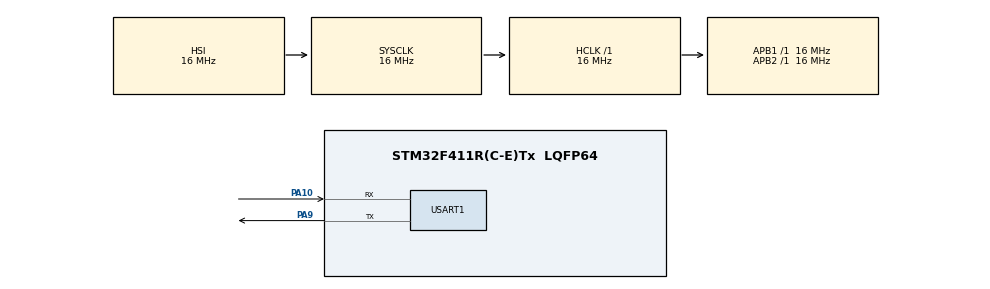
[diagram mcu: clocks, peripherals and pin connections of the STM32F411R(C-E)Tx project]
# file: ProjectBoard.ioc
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Mcu.Family=STM32F4
Mcu.Name=STM32F411R(C-E)Tx
Mcu.Package=LQFP64
NVIC.PriorityGroup=NVIC_PRIORITYGROUP_4
NVIC.USART1_IRQn=true\:0\:0\:false\:false\:true\:true\:true\:true
PA10.Mode=Asynchronous
PA10.Signal=USART1_RX
PA9.Mode=Asynchronous
PA9.Signal=USART1_TX
ProjectManager.HeapSize=0x200
ProjectManager.StackSize=0x400
ProjectManager.TargetToolchain=STM32CubeIDE
RCC.AHBFreq_Value=16000000
RCC.APB1Freq_Value=16000000
RCC.APB2Freq_Value=16000000
RCC.CortexFreq_Value=16000000
RCC.HSE_VALUE=25000000
RCC.HSI_VALUE=16000000
RCC.LSE_VALUE=32768
RCC.SYSCLKFreq_VALUE=16000000
RCC.VCOOutputFreq_Value=192000000
USART1.VirtualMode=VM_ASYNC
board=custom

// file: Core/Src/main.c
/* USER CODE BEGIN Header */
/**
  ******************************************************************************
  * @file           : main.c
  * @brief          : Main program body
  ******************************************************************************
  * @attention
  *
  * Copyright (c) 2024 STMicroelectronics.
  * All rights reserved.
  *
  * This software is licensed under terms that can be found in the LICENSE file
  * in the root directory of this software component.
  * If no LICENSE file comes with this software, it is provided AS-IS.
  *
  ******************************************************************************
  */
/* USER CODE END Header */
#include "main.h"
#include "time.h"
#include "stdio.h"
#include "string.h"
#include "stm32f4xx.h"
#include "delay.h"
#include "dht11.h"
#include "buzzer.h"
#include "ESPDataLogger.h"

UART_HandleTypeDef huart1;

void SystemClock_Config(void);
static void MX_GPIO_Init(void);
static void MX_USART1_UART_Init(void);
void Tim2_Init(void);
void TIM2_IRQHandler(void);

/* USER CODE BEGIN 0 */
float temp, hum;
uint16_t Value_Buf [1];
int confirmed = 0;
int program_counter = 0;
int reset = 0;
int send_OK = 0;
int counter = -1;
uint8_t Response = 0;
//int data = 73;
/* USER CODE END 0 */

int main(void)
{
  //Initialization
  HAL_Init();
  SystemClock_Config();
  MX_GPIO_Init();
  MX_USART1_UART_Init();

  //Enable Timer Interrupt for Software Reset
  Tim2_Init();
  TIM2->CR1 |= (1<<0);

  buzzer_init();
  buzzer_off();

  //WiFi Setup
  reset = 1;
  ESP_Init("EEE192-429", "EEE192_Room429");
  reset = 0;

  dht11_PinA8_Init();

  while (1)
  {
	  dht11_start();
	  if (Check_Response() == Response_OK) {
		  //DHT Read
		  Get_DHT_Data(&temp, &hum);
		  Value_Buf[0] = hum;
		}
	  //Value_Buf[0] = data;
	  if (hum >= 90) {
		  buzzer_on();
	  }
	  reset = 1;
	  confirmed = 0;
	  ESP_Send_Data("DJPDDIVVR9IA7VF7", 2, Value_Buf[0]);
	  reset = 0;
	  delay(1000);
  }
}

void SystemClock_Config(void)
{
  RCC_OscInitTypeDef RCC_OscInitStruct = {0};
  RCC_ClkInitTypeDef RCC_ClkInitStruct = {0};

  /** Configure the main internal regulator output voltage
  */
  __HAL_RCC_PWR_CLK_ENABLE();
  __HAL_PWR_VOLTAGESCALING_CONFIG(PWR_REGULATOR_VOLTAGE_SCALE1);

  /** Initializes the RCC Oscillators according to the specified parameters
  * in the RCC_OscInitTypeDef structure.
  */
  RCC_OscInitStruct.OscillatorType = RCC_OSCILLATORTYPE_HSI;
  RCC_OscInitStruct.HSIState = RCC_HSI_ON;
  RCC_OscInitStruct.HSICalibrationValue = RCC_HSICALIBRATION_DEFAULT;
  RCC_OscInitStruct.PLL.PLLState = RCC_PLL_NONE;
  if (HAL_RCC_OscConfig(&RCC_OscInitStruct) != HAL_OK)
  {
    Error_Handler();
  }

  /** Initializes the CPU, AHB and APB buses clocks
  */
  RCC_ClkInitStruct.ClockType = RCC_CLOCKTYPE_HCLK|RCC_CLOCKTYPE_SYSCLK
                              |RCC_CLOCKTYPE_PCLK1|RCC_CLOCKTYPE_PCLK2;
  RCC_ClkInitStruct.SYSCLKSource = RCC_SYSCLKSOURCE_HSI;
  RCC_ClkInitStruct.AHBCLKDivider = RCC_SYSCLK_DIV1;
  RCC_ClkInitStruct.APB1CLKDivider = RCC_HCLK_DIV1;
  RCC_ClkInitStruct.APB2CLKDivider = RCC_HCLK_DIV1;

  if (HAL_RCC_ClockConfig(&RCC_ClkInitStruct, FLASH_LATENCY_0) != HAL_OK)
  {
    Error_Handler();
  }
}

static void MX_USART1_UART_Init(void)
{

  huart1.Instance = USART1;
  huart1.Init.BaudRate = 115200;
  huart1.Init.WordLength = UART_WORDLENGTH_8B;
  huart1.Init.StopBits = UART_STOPBITS_1;
  huart1.Init.Parity = UART_PARITY_NONE;
  huart1.Init.Mode = UART_MODE_TX_RX;
  huart1.Init.HwFlowCtl = UART_HWCONTROL_NONE;
  huart1.Init.OverSampling = UART_OVERSAMPLING_16;
  if (HAL_UART_Init(&huart1) != HAL_OK)
  {
    Error_Handler();
  }

}

static void MX_GPIO_Init(void)
{

  /* GPIO Ports Clock Enable */
  __HAL_RCC_GPIOA_CLK_ENABLE();

}

void Error_Handler(void)
{
  __disable_irq();
  while (1)
  {
  }
}

void Tim2_Init(void){
    RCC->APB1ENR |= (1<<0); // Enable clock for TIM2
    TIM2->PSC = 42000-1;    // Set PSC+1 = 160000

    TIM2->ARR = 5700;        // Set timer to reset after CNT = 167 corresponds to 3Hz blinking (2+1 in STUDENT ID)

    TIM2->DIER |= (1<<0);   // Enable timer interrupt generation

    NVIC->IP[TIM2_IRQn] =  (2 << 4); // Set priority to 2
    NVIC->ISER[TIM2_IRQn >> 5] |= (1 << (TIM2_IRQn % 32)); // Enable interrupt
    TIM2->SR &= ~(1<<0);

    TIM2->EGR |= (1<<0);
    TIM2->CR1 &= ~(1<<0);    // Disable timer, for now
}

void TIM2_IRQHandler(void){
	program_counter +=1;
	if(reset == 1 && confirmed == 0){
		confirmed = 1; //do a confir test to avoid unnecesarry resets
	}
	else if(reset == 1 && confirmed == 1){
		NVIC_SystemReset(); //reset every time a confirmed disconnection
	}
    TIM2->SR &= ~(1<<0); // Clear UIF update interrupt flag
}
